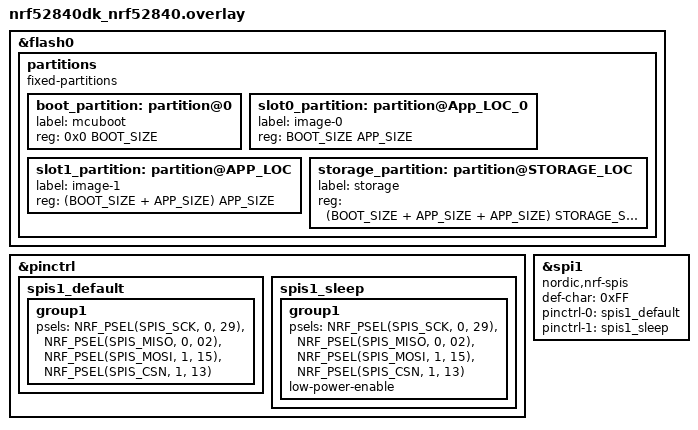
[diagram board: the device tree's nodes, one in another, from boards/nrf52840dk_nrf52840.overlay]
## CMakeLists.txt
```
cmake_minimum_required(VERSION 3.20.0)
find_package(Zephyr REQUIRED HINTS $ENV{ZEPHYR_BASE})

project(nrf_spi)

target_sources(app PRIVATE src/main.c)
set(BOARD nrf52840dk CACHE STRING "")
```

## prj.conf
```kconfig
CONFIG_GPIO=y
CONFIG_SPI=y
CONFIG_SPI_ASYNC=y
CONFIG_SPI_SLAVE=y

CONFIG_LOG=y
CONFIG_LOG_DEFAULT_LEVEL=3
```

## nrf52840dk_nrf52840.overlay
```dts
&pinctrl {
    spis1_default: spis1_default {
        group1 {
            psels = <NRF_PSEL(SPIS_SCK,  0, 29)>,
                    <NRF_PSEL(SPIS_MISO, 0, 02)>,
                    <NRF_PSEL(SPIS_MOSI, 1, 15)>,
                    <NRF_PSEL(SPIS_CSN,  1, 13)>;
        };
    };
    spis1_sleep: spis1_sleep {
        group1 {
            psels = <NRF_PSEL(SPIS_SCK,  0, 29)>,
                    <NRF_PSEL(SPIS_MISO, 0, 02)>,
                    <NRF_PSEL(SPIS_MOSI, 1, 15)>,
                    <NRF_PSEL(SPIS_CSN,  1, 13)>;
            low-power-enable;
        };
    };
};

/*
 * compatible = "nordic,nrf-spis" triggers DT_HAS_NORDIC_NRF_SPIS_ENABLED
 * which auto-selects NRFX_SPIS via SPI_NRFX_SPIS - no manual Kconfig needed
 * CSN pin is defined here in pinctrl, NOT via cs-gpios for SPIS
 */
&spi1 {
    compatible = "nordic,nrf-spis";
    status = "okay";
    def-char = <0xFF>;
    pinctrl-0 = <&spis1_default>;
    pinctrl-1 = <&spis1_sleep>;
    pinctrl-names = "default", "sleep";
};
```

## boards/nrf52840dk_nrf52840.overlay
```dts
/*
 * Sizes calculated as fractions of total flash.
 * Edit only these defines to rescale for any board.
 */
#define FLASH_TOTAL  0x100000 /* 1 MiB */
#define BOOT_SIZE     0xc000 
#define App_LOC_0     c000   
#define APP_LOC       82000  
#define APP_SIZE      0x76000
#define STORAGE_LOC  f8000
#define STORAGE_SIZE 0x8000

&flash0 {
    partitions {
        compatible = "fixed-partitions";
        #address-cells = <1>;
        #size-cells = <1>;


        boot_partition: partition@0 {
            label = "mcuboot";
            reg = <0x0 BOOT_SIZE>;
        };

        slot0_partition: partition@App_LOC_0 {
            label = "image-0";
            reg = <BOOT_SIZE APP_SIZE>;
        };

        slot1_partition: partition@APP_LOC {
            label = "image-1";
            reg = <(BOOT_SIZE + APP_SIZE) APP_SIZE>;
        };

        storage_partition: partition@STORAGE_LOC {
            label = "storage";
            reg = <(BOOT_SIZE + APP_SIZE + APP_SIZE) STORAGE_SIZE>;
        };
    };
};

&pinctrl {
    spis1_default: spis1_default {
        group1 {
            psels = <NRF_PSEL(SPIS_SCK,  0, 29)>,
                    <NRF_PSEL(SPIS_MISO, 0, 02)>,
                    <NRF_PSEL(SPIS_MOSI, 1, 15)>,
                    <NRF_PSEL(SPIS_CSN,  1, 13)>;
        };
    };
    spis1_sleep: spis1_sleep {
        group1 {
            psels = <NRF_PSEL(SPIS_SCK,  0, 29)>,
                    <NRF_PSEL(SPIS_MISO, 0, 02)>,
                    <NRF_PSEL(SPIS_MOSI, 1, 15)>,
                    <NRF_PSEL(SPIS_CSN,  1, 13)>;
            low-power-enable;
        };
    };
};

/*
 * compatible = "nordic,nrf-spis" triggers DT_HAS_NORDIC_NRF_SPIS_ENABLED
 * which auto-selects NRFX_SPIS via SPI_NRFX_SPIS - no manual Kconfig needed
 * CSN pin is defined here in pinctrl, NOT via cs-gpios for SPIS
 */
&spi1 {
    compatible = "nordic,nrf-spis";
    status = "okay";
    def-char = <0xFF>;
    pinctrl-0 = <&spis1_default>;
    pinctrl-1 = <&spis1_sleep>;
    pinctrl-names = "default", "sleep";
};
```

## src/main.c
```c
#include <zephyr/kernel.h>
#include <zephyr/device.h>
#include <zephyr/drivers/spi.h>
#include <zephyr/logging/log.h>

LOG_MODULE_REGISTER(spi_slave, LOG_LEVEL_DBG);

/* ------------------------------------------------------------------ */
/*  Devicetree reference                                               */
/* ------------------------------------------------------------------ */
#define SPI_SLAVE_NODE  DT_NODELABEL(spi1)
#define BUF_SIZE        32

/* ------------------------------------------------------------------ */
/*  Buffers  (must be in RAM)                                          */
/* ------------------------------------------------------------------ */
static uint8_t tx_buf[BUF_SIZE];
static uint8_t rx_buf[BUF_SIZE];

/* ------------------------------------------------------------------ */
/*  Semaphore for async callback -> main thread signalling             */
/* ------------------------------------------------------------------ */
static K_SEM_DEFINE(spis_sem, 0, 1);
static int spis_result;

/* ------------------------------------------------------------------ */
/*  Async callback (runs in ISR context)                               */
/* ------------------------------------------------------------------ */
static void spi_slave_cb(const struct device *dev,
                         int                  result,
                         void                *userdata)
{
    ARG_UNUSED(dev);
    ARG_UNUSED(userdata);

    spis_result = result;
    k_sem_give(&spis_sem);
}

/* ------------------------------------------------------------------ */
/*  SPI slave configuration                                            */
/* ------------------------------------------------------------------ */
static const struct spi_config spis_cfg = {
    /*
     * SPI_OP_MODE_SLAVE  : operate as peripheral/slave
     * SPI_WORD_SET(8)    : 8-bit words
     * SPI_TRANSFER_MSB   : MSB first
     *
     * Add SPI_MODE_CPOL / SPI_MODE_CPHA if your master uses Mode 1/2/3
     * Mode 0 (default): CPOL=0, CPHA=0
     * Mode 3          : CPOL=1, CPHA=1  -> SPI_MODE_CPOL | SPI_MODE_CPHA
     */
    .operation = SPI_OP_MODE_SLAVE  |
                 SPI_WORD_SET(8)    |
                 SPI_TRANSFER_MSB,
    .frequency = 0,    /* ignored in slave mode */
    .slave     = 0,
};

/* ------------------------------------------------------------------ */
/*  Helpers                                                            */
/* ------------------------------------------------------------------ */
static void prepare_tx_buf(void)
{
    /* Pre-load a response for the master to read */
    for (int i = 0; i < BUF_SIZE; i++) {
        tx_buf[i] = (uint8_t)(0xA0 + i);
    }
}

static void process_rx_data(int len)
{
    LOG_INF("Received %d bytes from master", len);
    LOG_HEXDUMP_INF(rx_buf, len, "RX");

    /* Echo: copy received data into tx for next transaction */
    memcpy(tx_buf, rx_buf, len);
}

/* ------------------------------------------------------------------ */
/*  Main                                                               */
/* ------------------------------------------------------------------ */
int main(void)
{
    int ret;

    LOG_INF("SPI Slave example - nRF52840 (nCS v3.2.1)");

    /* Get SPI device from devicetree */
    const struct device *spis_dev = DEVICE_DT_GET(SPI_SLAVE_NODE);

    if (!device_is_ready(spis_dev)) {
        LOG_ERR("SPI slave device not ready");
        return -ENODEV;
    }

    LOG_INF("SPI slave device ready");

    while (1) {
        /* Prepare buffers for next transaction */
        prepare_tx_buf();
        memset(rx_buf, 0, sizeof(rx_buf));

        struct spi_buf tx_spi_buf    = { .buf = tx_buf, .len = BUF_SIZE };
        struct spi_buf rx_spi_buf    = { .buf = rx_buf, .len = BUF_SIZE };
        struct spi_buf_set tx_set    = { .buffers = &tx_spi_buf, .count = 1 };
        struct spi_buf_set rx_set    = { .buffers = &rx_spi_buf, .count = 1 };

        /*
         * spi_transceive_cb() arms the slave and returns immediately.
         * The callback fires when a master transaction completes.
         */
        ret = spi_transceive_cb(spis_dev,
                                &spis_cfg,
                                &tx_set,
                                &rx_set,
                                spi_slave_cb,
                                NULL);
        if (ret < 0) {
            LOG_ERR("spi_transceive_cb failed: %d", ret);
            k_sleep(K_MSEC(100));
            continue;
        }

        LOG_DBG("Waiting for master transaction...");

        /* Block until callback signals completion */
        k_sem_take(&spis_sem, K_FOREVER);

        if (spis_result < 0) {
            LOG_ERR("SPI transfer error: %d", spis_result);
            continue;
        }

        /* Process the received data */
        process_rx_data(BUF_SIZE);
    }

    return 0;
}
```
